# ESP32C5_RADIO register map
Vendor: Espressif; Series: ESP32-C5; File version: 0.1
Registers are 32-bit, read-write, no defined reset value unless marked. A register's access mark holds for its fields unless they carry their own. Offsets are from the block's base; [hi:lo] are bit positions; {n}, {i} and the like mark numbered series.

## WIFI_MAC_BSSID_POLICY — Per-interface BSSID address and policy words used by scan and associated-STA receive filtering.
Base 0x600A4000
{0x0+8i} BSSID_LOW{i} (i=0..3) — Project-assigned name. BSSID bytes 0..3 for interfaces 0..3; hal_mac_set_bssid publishes a complete full-word store.
  [31:0] BYTES_0_3 — Project-assigned name.
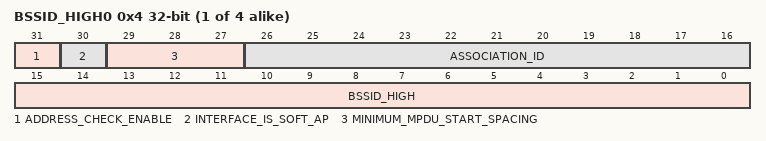
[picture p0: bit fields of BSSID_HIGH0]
{0x4+8i} BSSID_HIGH{i} (i=0..3) — Project-assigned name. Canonical high BSSID, association identity and interface policy word for interfaces 0..3. Complete dbg_read_rx_misc independently decodes every field; the HE association leaf updates the MMSS/AID fields of interface zero rather than defining a second register identity.
  [31] ADDRESS_CHECK_ENABLE — Project-assigned name. MACBSSID_EN: hal_mac_set_bssid clears this bit before changing the address and sets it after publication; the reachable associated-STA policy branch also sets it.
  [30] INTERFACE_IS_SOFT_AP — Project-assigned name. Cleared for interface zero by the associated-STA policy-five transaction.
  [29:27] MINIMUM_MPDU_START_SPACING — Project-assigned name. Three-bit MMSS value printed by dbg_read_rx_misc.
  [26:16] ASSOCIATION_ID — Project-assigned name. Eleven-bit AID printed by dbg_read_rx_misc.
  [15:0] BSSID_HIGH — Project-assigned name.

## WIFI_MAC_STA_BEACON_FILTER — Station beacon-filter control word recovered from the complete enable and disable leaves. The three low bits are toggled together; individual hardware meanings remain unknown.
Base 0x600A42B4
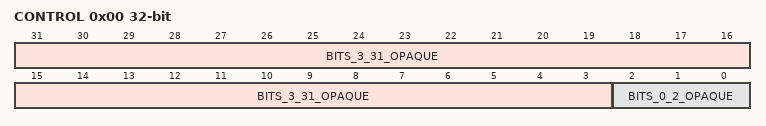
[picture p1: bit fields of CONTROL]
0x00 CONTROL — Project-assigned name. hal_enable_sta_beacon_filter sets bits 2:0 after enabling the matching interrupt; hal_disable_sta_beacon_filter clears them before disabling that interrupt.
  [31:3] BITS_3_31_OPAQUE — Opaque: meaning not established. Observed source use; the individual hardware meaning is unknown.
  [2:0] BITS_0_2_OPAQUE — Opaque: meaning not established.

## WIFI_MAC_STA_TSF_LOAD — Shared station TSF load and coherent snapshot transaction.
Base 0x600AD814
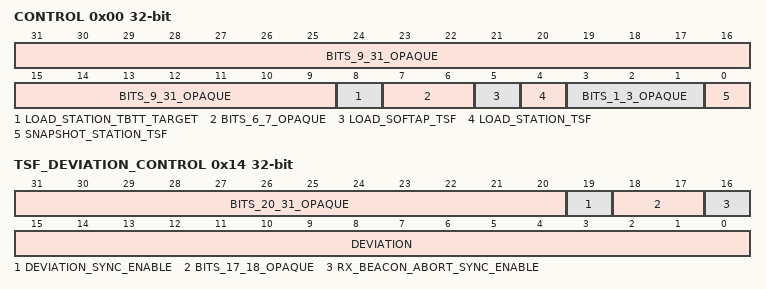
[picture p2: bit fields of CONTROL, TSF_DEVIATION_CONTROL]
0x00 CONTROL — Project-assigned name. Complete hal_set_sta_tsf asserts bit four after writing both station TSF value words; the SoftAP path of complete hal_mac_tsf_reset asserts bit five after clearing both shared TSF value words; complete libpp[hal_tsf.o]::hal_get_sta_tsf sets then clears bit zero around its snapshot reads.
  [31:9] BITS_9_31_OPAQUE — Opaque: meaning not established. Observed source use; the individual hardware meaning is unknown.
  [8] LOAD_STATION_TBTT_TARGET — Project-assigned name. Complete hal_set_sta_tbtt and the index-0 TBTT start-time leaf set this bit after writing the station TBTT target.
  [7:6] BITS_6_7_OPAQUE — Opaque: meaning not established. Observed source use; the individual hardware meaning is unknown.
  [5] LOAD_SOFTAP_TSF — Project-assigned name. SoftAP TSF load request asserted after the two zero-value writes by the arg0=0 path of complete hal_mac_tsf_reset.
  [4] LOAD_STATION_TSF — Project-assigned name. Station TSF load request asserted by the final fresh-read RMW in hal_set_sta_tsf.
  [3:1] BITS_1_3_OPAQUE — Opaque: meaning not established. Observed source use; the individual hardware meaning is unknown.
  [0] SNAPSHOT_STATION_TSF — Project-assigned name. Complete libpp[hal_tsf.o]::hal_get_sta_tsf sets this bit before either station TSF word is sampled and clears it after the optional reads.
0x04 VALUE_LOW wo — Project-assigned name. Low 32 bits written first by complete hal_set_sta_tsf.
  [31:0] VALUE — Project-assigned name.
0x08 VALUE_HIGH wo — Project-assigned name. High 32 bits written second by complete hal_set_sta_tsf.
  [31:0] VALUE — Project-assigned name.
0x0C SNAPSHOT_LOW ro — Project-assigned name. Coherently latched low 32 bits conditionally read by complete libpp[hal_tsf.o]::hal_get_sta_tsf.
  [31:0] VALUE — Project-assigned name.
0x10 SNAPSHOT_HIGH ro — Project-assigned name. Coherently latched high 32 bits conditionally read by complete libpp[hal_tsf.o]::hal_get_sta_tsf.
  [31:0] VALUE — Project-assigned name.
0x14 TSF_DEVIATION_CONTROL — Project-assigned name. Complete ROM leaves independently replace the TSF deviation value and set two synchronization controls; omitted bits remain semantically unknown.
  [31:20] BITS_20_31_OPAQUE — Opaque: meaning not established. Observed source use; the individual hardware meaning is unknown.
  [19] DEVIATION_SYNC_ENABLE — Project-assigned name.
  [18:17] BITS_17_18_OPAQUE — Opaque: meaning not established. Observed source use; the individual hardware meaning is unknown.
  [16] RX_BEACON_ABORT_SYNC_ENABLE — Project-assigned name.
  [15:0] DEVIATION — Project-assigned name.
